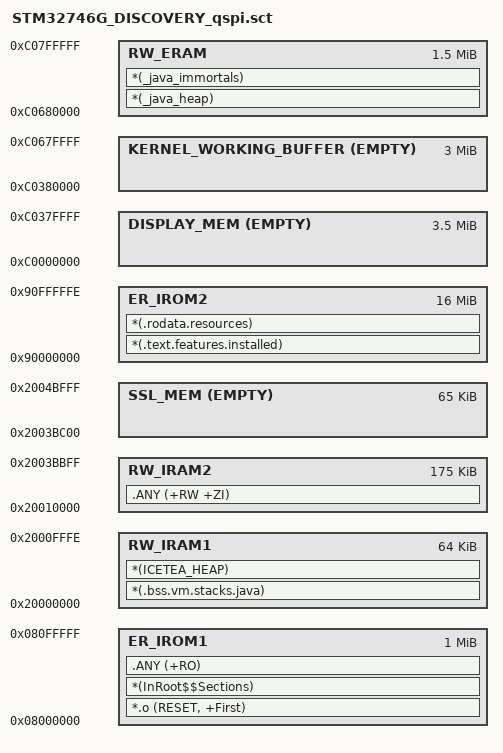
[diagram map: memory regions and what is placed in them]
; *************************************************************
; *** Scatter-Loading Description File generated by uVision ***
; *************************************************************

LR_IROM1 0x08000000 0x00100000  {    ; load region size_region
  ER_IROM1 0x08000000 0x00100000  {  ; load address = execution address
   *.o (RESET, +First)
   *(InRoot$$Sections)
   .ANY (+RO)
  }
  RW_IRAM1 0x20000000 0x0000FFFF  {  ; DTCM (used by Ethernet DMA buffers)
   *(.bss.vm.stacks.java)
   *(ICETEA_HEAP)
  }
  RW_IRAM2 0x20010000 0x0002BC00  {  ; Internal RAM (RW Data)
   .ANY (+RW +ZI)
  }
  SSL_MEM 0x2003BC00 EMPTY 0x10400  {  ; Internal RAM (RW Data)
	; Empty region for placing the SSL allocator
  }
  
 ; SDRAM: FIXME: update main.c / MPU_Config() when this layout changes
  
  DISPLAY_MEM 0xC0000000 EMPTY 0x380000 {
	; Empty region reserved for display stack buffers
  }
  KERNEL_WORKING_BUFFER 0xC0380000 EMPTY 0x300000     ;
  {
    ; Empty region for placing the KF allocator
  }
  RW_ERAM 0xC0680000 0x180000 {
	*(_java_heap)
	*(_java_immortals)
  }
}

LR_ROM1 0x90000000 0x90FFFFFF  {    ; load region size_region
  ER_IROM2 0x90000000 0x00FFFFFF  {  ; load address = execution address
	*(.text.features.installed)
	*(.rodata.resources)
  }
}

